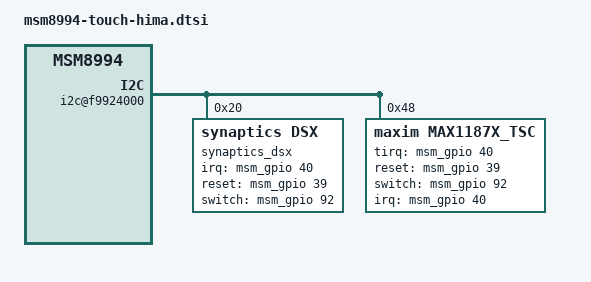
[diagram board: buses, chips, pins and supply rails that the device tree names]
&pmx_ts {
	qcom,pins = <&gp 40>;
	qcom,pin-func = <0>;
	qcom,num-grp-pins = <1>;
};

&ts_active {
	drive-strength = <2>;
	bias-pull-up;
};

&ts_suspend {
	drive-strength = <2>;
	bias-pull-up;
};

&soc {
	touch_fw_update {
		compatible = "htc,touch_fwu";
	};

	i2c@f9924000 {
		synaptics_dsx@20 {
			compatible = "synaptics,dsx";
			reg = <0x20>;
			interrupt-parent = <&msm_gpio>;
			interrupts = <40 0x2>;
			synaptics,irq-gpio = <&msm_gpio 40 0x00>;
			synaptics,irq-flags = <0x2008>;
			synaptics,reset-gpio = <&msm_gpio 39 0x00>;
			synaptics,reset-on-state = <0>;
			synaptics,reset-active-ms = <1>;
			synaptics,reset-delay-ms = <20>;
			synaptics,switch-gpio = <&msm_gpio 92 0x00>;
			synaptics,update-feature = <2>;
			synaptics,support-glove = <1>;
			synaptics,support-cover = <1>;
			synaptics,hall-block-time = <1000>;
			synaptics,display-coords = <0 1080 0 1920>;
			pinctrl-names = "pmx_ts_active", "pmx_ts_suspend";
			pinctrl-0 = <&ts_active>;
			pinctrl-1 = <&ts_suspend>;

			config_5 {
				pr_number     = <1826300>;
				uncover_setting = [FC C0 19 1E 80 08 52 48 01 D2];
				cover_setting = [FC C0 0D 0F 50 32 1A 0D 00 A0];
				glove_setting = [FA E6 19 1E 50 19 40 1A 00 D2];
				config = [
					02 12 00 00 04 2F 03 02
					05 37 04 7F 07 C3 41 F6
					40 00 00 20 00 0F 1B 01
					1E 05 E4 15 9E 05 28 37
					FE 3A FE 63 CA BE DA FC
					3C C0 C4 05 03 19 1E 80
					0F 0A 78 00 01 01 07 04
					04 32 28 08 C8 71 71 FF
					FF F1 F4 52 48 01 40 28
					2D FF 00 00 00 00 01 05
					0A 01 FF 00 D2 00 80 03
					1B 00 00 FF 64 00 FF FF
					A6 C8 00 7D 00 E6 80 00
					00 00 00 14 00 00 00 3A
					02 32 21 0C 0C 30 30 00
					31 1D 64 00 00 C8 00 01
					00 05 05 07 07 02 58 02
					01 03 01 14 00 14 00 00
					00 03 00 02 2C 81 14 00
					14 00 00 02 05 00 03 2C
					01 14 00 14 00 00 04 02
					00 01 28 01 14 00 14 00
					00 06 02 00 01 2A 81 14
					00 14 00 00 08 02 00 01
					2C 01 14 00 14 00 00 0A
					02 00 01 2C 83 26 00 26
					00 00 00 05 00 03 2C 83
					26 00 26 00 00 02 02 00
					01 28 03 26 00 26 00 00
					05 02 00 01 2A 02 21 00
					21 00 00 08 02 00 01 2D
					02 21 00 21 00 00 0C 05
					00 02 28 01 1C 00 1C 00
					00 0F 05 00 02 29 00 00
					00 00 00 00 00 00 00 00
					00 00 00 00 00 00 00 00
					00 00 1A 00 03 00 64 00
					14 0A 05 01 28 27 27 28
					01 01 34 00 03 00 00 00
					00 00 32 00 06 08 04 01
					07 02 01 02 00 1B 10 08
					03 11 05 73 0A C8 14 30
					46 80 05 14 B4 04 01 02
					00 04 0D 18 16 15 14 13
					12 0F 0E 0C 0B 0A 09 08
					04 07 FF FF FF FF FF 00
					01 02 03 04 05 06 07 08
					09 0A 0B 0C 0D 0E 0F 10
					11 12 13 14 15 16 17 18
					19 1A FF FF FF FF FF 00
					10 00 10 00 10 00 10 73
					7A 80 80 80 80 80 80 80
					80 80 80 80 80 80 80 80
					80 7A 73 80 80 80 80 80
					80 80 80 80 80 80 80 80
					80 80 80 80 80 80 80 80
					80 80 80 80 80 80 80 80
					80 80 80 00 10 00 10 00
					10 00 10 00 44 20 01 04
					0A 05
				];
			};

			config_4 {
				pr_number     = <1817745>;
				config = [
					20 15 01 19 00 2F 03 02
					05 37 04 7F 07 C3 41 F6
					40 00 00 00 00 0F 1B 01
					1E 05 E4 15 9E 05 28 37
					FE 3A FE 63 CA BE DA AA
					3C E6 C4 05 05 19 1E 80
					0F 0A 78 00 01 01 07 04
					04 1E 28 19 C8 71 71 FF
					FF F1 F4 52 48 00 40 28
					2D FF 00 00 00 00 01 05
					0A 01 FF 00 D2 00 80 03
					1B 00 00 FF 64 00 FF FF
					BF 96 00 7D 00 E6 80 00
					00 00 00 14 00 00 00 3A
					02 32 21 0C 0C 30 30 00
					31 01 64 00 00 C8 00 01
					00 05 05 07 07 02 64 00
					01 03 01 14 00 14 00 00
					00 03 00 02 2C 81 14 00
					14 00 00 02 05 00 03 2C
					01 14 00 14 00 00 04 02
					00 01 28 01 14 00 14 00
					00 06 02 00 01 2A 81 14
					00 14 00 00 08 02 00 01
					2C 01 14 00 14 00 00 0A
					02 00 01 2C 83 26 00 26
					00 00 00 05 00 03 2C 83
					26 00 26 00 00 02 02 00
					01 28 03 26 00 26 00 00
					05 02 00 01 2A 02 21 00
					21 00 00 08 02 00 01 2D
					02 21 00 21 00 00 0C 05
					00 02 28 01 1C 00 1C 00
					00 0F 05 00 02 29 00 00
					00 00 00 00 00 00 00 00
					00 00 00 00 00 00 00 00
					00 00 1A 00 03 00 A6 00
					14 0A 05 01 28 27 27 28
					01 01 34 00 03 00 00 00
					00 00 32 00 06 08 04 01
					07 02 01 02 00 1B 18 0C
					03 11 05 73 0A C8 14 20
					46 80 05 14 B4 04 01 02
					00 04 0D 18 16 15 14 13
					12 0F 0E 0C 0B 0A 09 08
					04 07 FF FF FF FF FF 00
					01 02 03 04 05 06 07 08
					09 0A 0B 0C 0D 0E 0F 10
					11 12 13 14 15 16 17 18
					19 1A FF FF FF FF FF 00
					10 00 10 00 10 00 10 73
					7A 80 80 80 80 80 80 80
					80 80 80 80 80 80 80 80
					80 7A 73 80 80 80 80 80
					80 80 80 80 80 80 80 80
					80 80 80 80 80 80 80 80
					80 80 80 80 80 80 80 80
					80 80 80 00 10 00 10 00
					10 00 10 00 44 20 01 02
					0A 02
				];
			};

			config_3 {
				pr_number     = <1812806>;
				config = [
					20 14 01 08 04 0F 03 02
					05 37 04 7F 07 C3 41 F6
					40 00 00 00 00 0F 1B 01
					1E 05 E4 15 9E 05 2D 37
					FE 3A FE 63 CA BE DA AA
					3C E6 C4 05 05 19 1E 80
					0F 0A 78 00 01 01 07 04
					04 0A C0 0A C8 71 71 FF
					FF F1 F4 40 19 00 40 28
					26 FF 00 00 00 00 01 21
					0A 01 FF 00 D2 00 80 03
					1B 00 00 FF 64 00 FF FF
					BF 96 00 7D 00 E6 80 00
					00 00 00 14 00 00 00 3A
					02 32 21 0C 0C 30 30 00
					31 01 64 00 00 C8 00 01
					00 05 05 07 07 02 64 00
					01 03 01 14 00 14 00 00
					00 03 00 02 2C 81 14 00
					14 00 00 02 05 00 03 2C
					01 14 00 14 00 00 04 02
					00 01 28 01 14 00 14 00
					00 06 02 00 01 2A 81 14
					00 14 00 00 08 02 00 01
					2C 01 14 00 14 00 00 0A
					02 00 01 2C 83 26 00 26
					00 00 00 05 00 03 2C 83
					26 00 26 00 00 02 02 00
					01 28 03 26 00 26 00 00
					05 02 00 01 2A 02 21 00
					21 00 00 08 02 00 01 2D
					02 21 00 21 00 00 0C 05
					00 02 28 01 1C 00 1C 00
					00 0F 05 00 02 29 00 00
					00 00 00 00 00 00 00 00
					00 00 00 00 00 00 00 00
					00 00 1A 00 03 00 A6 00
					14 0A 05 01 28 27 27 28
					01 01 34 00 03 00 00 00
					00 00 32 00 06 08 04 01
					07 02 01 02 00 1B 18 0C
					03 11 05 73 0A C8 14 20
					46 80 05 14 B4 04 01 02
					00 04 0D 18 16 15 14 13
					12 0F 0E 0C 0B 0A 09 08
					04 07 FF FF FF FF FF 00
					01 02 03 04 05 06 07 08
					09 0A 0B 0C 0D 0E 0F 10
					11 12 13 14 15 16 17 18
					19 1A FF FF FF FF FF 00
					10 00 10 00 10 00 10 73
					7A 80 80 80 80 80 80 80
					80 80 80 80 80 80 80 80
					80 7A 73 80 80 80 80 80
					80 80 80 80 80 80 80 80
					80 80 80 80 80 80 80 80
					80 80 80 80 80 80 80 80
					80 80 80 00 10 00 10 00
					10 00 10 00 55 50 01 02
					0A 02
				];
			};

			config_2 {
				pr_number     = <1776733>;
				config = [
					20 14 12 11 04 0F 03 02
					05 37 04 7F 07 C3 41 F6
					40 00 00 00 00 0F 1B 01
					1E 05 E4 15 9E 05 2D 37
					FE 3A FE 63 CA BE DA AA
					3C E6 C4 05 05 19 1E 80
					0F 0A 78 00 01 01 07 04
					04 0A C0 19 C8 71 71 FF
					FF F1 F4 40 19 00 40 28
					26 FF 00 00 00 00 01 21
					0A 01 FF 00 D2 00 80 03
					1B 00 00 FF 64 00 FF FF
					BF 96 00 7D 00 E6 80 80
					0A 00 00 00 00 14 00 00
					00 3A 02 32 21 0C 0C 30
					30 00 31 01 64 00 00 C8
					00 01 00 05 05 07 07 02
					64 00 01 03 01 14 00 14
					00 00 00 03 00 02 2C 81
					14 00 14 00 00 02 05 00
					03 2C 01 14 00 14 00 00
					04 02 00 01 28 01 14 00
					14 00 00 06 02 00 01 2A
					81 14 00 14 00 00 08 02
					00 01 2C 01 14 00 14 00
					00 0A 02 00 01 2C 83 26
					00 26 00 00 00 05 00 03
					2C 83 26 00 26 00 00 02
					02 00 01 28 03 26 00 26
					00 00 05 02 00 01 2A 02
					21 00 21 00 00 08 02 00
					01 2D 02 21 00 21 00 00
					0C 05 00 02 28 01 1C 00
					1C 00 00 0F 05 00 02 29
					00 00 00 00 00 00 00 00
					00 00 00 00 00 00 00 00
					00 00 00 00 1A 00 03 00
					A6 00 14 0A 05 01 28 27
					27 28 01 01 34 00 03 00
					00 00 00 00 32 00 06 08
					04 01 07 02 01 02 00 1B
					18 0C 03 11 05 73 0A C8
					14 20 46 80 05 14 B4 04
					01 02 00 04 00 00 00 FF
					FF FF FF FF FF FF FF 51
					51 51 51 CD 0D 04 83 10
					10 10 10 0D 18 16 15 14
					13 12 0F 0E 0C 0B 0A 09
					08 04 07 FF FF FF FF FF
					00 01 02 03 04 05 06 07
					08 09 0A 0B 0C 0D 0E 0F
					10 11 12 13 14 15 16 17
					18 19 1A FF FF FF FF FF
					00 10 00 10 00 10 00 10
					73 7A 80 80 80 80 80 80
					80 80 80 80 80 80 80 80
					80 80 7A 73 80 80 80 80
					80 80 80 80 80 80 80 80
					80 80 80 80 80 80 80 80
					80 80 80 80 80 80 80 80
					80 80 80 80 00 10 00 10
					00 10 00 10 00 37 37 01
					02 0A 02
				];
			};

			config_1 {
				pr_number     = <1774299>;
				config = [
					20 14 11 06 04 0F 03 02
					05 37 04 7F 07 C3 41 F6
					40 00 00 00 00 0F 1B 01
					1E 05 E4 15 9E 05 2D 37
					FE 3A FE 63 CA BE DA AA
					3C E6 C4 05 05 19 1E 80
					0F 0A 8C 00 01 01 07 04
					04 0A C0 19 C8 71 71 FF
					FF F1 F4 40 19 00 40 40
					32 FF 00 00 00 00 00 21
					0A 01 FF 00 D2 00 80 03
					1B 00 00 FF 64 00 FF FF
					BF 96 D0 07 00 C0 80 80
					0A 00 00 00 00 14 00 00
					00 3A 02 32 21 0C 0C 30
					30 00 31 01 64 00 00 C8
					00 01 00 05 05 07 07 02
					F4 01 01 03 01 14 00 14
					00 00 00 03 00 02 2C 01
					14 00 14 00 02 00 05 00
					03 2C 01 14 00 14 00 04
					00 02 00 01 28 01 14 00
					14 00 06 00 02 00 01 2A
					81 14 00 14 00 08 00 02
					00 01 2C 01 14 00 14 00
					0A 00 02 00 01 2C 03 26
					00 26 00 00 00 05 00 03
					2C 03 26 00 26 00 00 02
					02 00 01 28 03 26 00 26
					00 00 05 02 00 01 2A 02
					21 00 21 00 00 08 02 00
					01 2D 02 21 00 21 00 00
					0C 05 00 02 28 01 1C 00
					1C 00 00 0F 05 00 02 29
					00 00 00 00 00 00 00 00
					00 00 00 00 00 00 00 00
					00 00 00 00 1A 00 03 00
					A6 00 14 0A 05 01 28 27
					27 28 01 01 34 00 03 00
					00 00 00 00 32 00 06 08
					04 01 07 02 01 02 00 1B
					10 0C 03 11 0A 73 0A C8
					14 20 46 80 03 14 00 04
					01 02 00 04 00 00 00 FF
					FF FF FF FF FF FF FF 51
					51 51 51 CD 0D 04 83 10
					10 10 10 0D 18 16 15 14
					13 12 0F 0E 0C 0B 0A 09
					08 04 07 FF FF FF FF FF
					00 01 02 03 04 05 06 07
					08 09 0A 0B 0C 0D 0E 0F
					10 11 12 13 14 15 16 17
					18 19 1A FF FF FF FF FF
					00 10 00 10 00 10 00 10
					80 80 80 80 80 80 80 80
					80 80 80 80 80 80 80 80
					80 80 80 80 80 80 80 80
					80 80 80 80 80 80 80 80
					80 80 80 80 80 80 80 80
					80 80 80 80 80 80 80 80
					80 80 80 80 00 10 00 10
					00 10 00 10 00 37 37 00
					00 02 0A 00
				];
			};

			config_0 {
				pr_number     = <1757676>;
				config = [
					20 14 10 17 04 0E 03 02
					05 37 04 7F 07 C3 41 F6
					40 00 00 00 00 0F 1B 01
					1E 05 E4 15 9E 05 2D 37
					FE 3A FE 63 CA BE DA 86
					80 C4 C4 05 03 20 32 80
					0F 0A 20 00 01 01 07 04
					04 0A C0 19 64 26 26 80
					80 00 00 6E 19 01 40 40
					32 FF 00 00 00 00 00 00
					25 0A 01 FF 00 D3 00 80
					04 1B 00 00 FF 63 07 FF
					FF BF 96 B8 0B 00 C0 80
					80 0A 00 00 00 00 14 00
					00 00 3A 02 32 21 0C 0C
					30 30 00 31 1D 66 00 00
					28 00 63 00 04 04 00 00
					00 B1 08 01 03 00 1C 00
					14 00 00 00 02 00 01 2B
					00 1C 00 14 00 00 02 02
					00 01 28 80 1C 00 14 00
					00 05 02 00 01 2A 80 1A
					00 14 00 00 08 02 00 01
					2D 80 1A 00 14 00 00 0A
					05 00 02 28 80 1A 00 14
					00 00 0A 05 00 02 29 83
					26 00 26 00 00 00 05 00
					03 2C 83 26 00 26 00 00
					02 02 00 01 28 83 26 00
					26 00 00 05 02 00 01 2A
					83 26 00 26 00 00 08 02
					00 01 2D 83 26 00 26 00
					00 0A 05 00 02 28 83 26
					00 26 00 00 0A 05 00 02
					29 03 04 07 03 06 06 06
					06 06 06 06 03 03 03 03
					00 00 00 00 00 18 00 03
					00 A6 00 14 64 05 01 28
					27 27 28 02 35 01 01 34
					00 03 00 02 00 00 00 32
					00 00 08 04 01 07 02 01
					02 00 1B 1C 0C 03 11 0A
					32 0A 32 14 20 46 80 03
					14 4B 04 01 02 00 04 00
					00 00 FF FF FF FF FF FF
					FF FF 51 51 51 51 CD 0D
					04 83 10 10 10 10 0D 18
					16 15 14 13 12 0F 0E 0C
					0B 0A 09 08 04 07 FF FF
					FF FF FF 00 01 02 03 04
					05 06 07 08 09 0A 0B 0C
					0D 0E 0F 10 11 12 13 14
					15 16 17 18 19 1A FF FF
					FF FF FF 00 10 00 10 00
					10 00 10 80 80 80 80 80
					80 80 80 80 80 80 80 80
					80 80 80 80 80 80 80 80
					80 80 80 80 80 80 80 80
					80 80 80 80 80 80 80 80
					80 80 80 80 80 80 80 80
					80 80 80 80 80 80 80 00
					10 00 10 00 10 00 10 00
					FF
				];
			};
		};

		maxim@48 {
			compatible = "maxim,max1187x_tsc";
			reg = <0x48>;
			interrupt-parent = <&msm_gpio>;
			interrupts = <40 0>;
			gpio_tirq = <&msm_gpio 40 0x00>;
			gpio_reset = <&msm_gpio 39 0x00>;
			gpio_switch = <&msm_gpio 92 0x00>;
			num_fw_mappings = <1>;
			chip_id = <0x78>;
			filename = "max11876a.bin";
			filesize = <0xC000>;
			file_codesize = <0xC000>;
			defaults_allow = <1>;
			default_config_id = <0x46D0>;
			default_chip_id = <0x78>;
			i2c_words = <123>;
			coordinate_settings = <0x4>;
			panel_min_x = <0>;
			panel_max_x = <1620>;
			panel_min_y = <0>;
			panel_max_y = <2880>;
			lcd_x = <1080>;
			lcd_y = <1920>;
			num_rows = <28>;
			num_cols = <16>;
			input_protocol = <1>;
			button_code0 = <0>;
			button_code1 = <0>;
			button_code2 = <0>;
			button_code3 = <0>;
			update_feature = <2>;
			tw_mask = <0xF>;
			report_mode = <2>;
			hall_block_touch_time = <1000>;
			pinctrl-names = "pmx_ts_active", "pmx_ts_suspend";
			pinctrl-0 = <&ts_active>;
			pinctrl-1 = <&ts_suspend>;

			config3 {
				config_id = <0x46D0>;
				chip_id = <0x78>;
				major_ver = <1>;
				minor_ver = <31>;
				protocol_ver = <8>;
				vendor_pin = <0xC>;
				support_glove = <1>;
				support_cover = <1>;
				filter_range = <0 30 75 75>;
				config_touch = [
					46D0 101C 007D 001E 0A02 0809 0704 0605
					FF03 FF02 01FF 00FF FF0D 0B0A 0C0E 0FFF
					11FF 1210 FFFF 1513 FF14 1716 1918 FFFF
					1B1A 0100 0302 0504 0706 0908 0B0A 0D0C
					0F0E FFFF FFFF FFFF FFFF FFFF FFFF FFFF
					FFFF 0B3F 8653 0513 0001 0502 079E 03E8
					0A8C 05DC 00A0 0D00 0A05 FFFF FFFF FFFF
					FFFF 03E8 FFFF FFFF FFFF FFFF FFFF FFFF
					3487
				];
				config_cal = [
					FFF5 FFEA FFDF 001C 001C 001C 001C 001C
					001C 001C 001C 001C 001C 001C 001C 001C
					001C 001C 001C 001C 001C 001C 001C 001C
					001C 001C 001C 0003 0003 0003 0003 0003
					0003 0003 0003 0003 0003 0003 0003 0003
					0003 0003 0003 0000 0000 0000 0000 0000
					0000 0000 0000 FFFF FF1E 00FF 010E 010E
					0104 00E1 0113 0113 00F5 00F5 000A 0001
					0001 0002 0002 0003 0001 0001 0002 0002
					0003 0AD7
				];
				config_private = [
					01E0 00FA 002D 038B FB08 0028 001E 0190
					02EE 00AA 0064 0018 04E2 0096 0000 B232
					0000 3200 FEFE FFFF 00FF FF15 4E21 0503
					7896 52EE FFFF FFFF FFFF FFFF FFFF FFFF
					FFFF 0EE0
				];
				config_lin_x = [
					002D 361E 664E 8D7D AD9D CDBD EDDD 934D
				];
				config_lin_y = [
					0030 3820 6850 9080 B0A0 D0C0 F0E0 A360
				];
			};

			config2 {
				config_id = <0x4301>;
				chip_id = <0x78>;
				major_ver = <1>;
				minor_ver = <31>;
				protocol_ver = <8>;
				vendor_pin = <0xD>;
				support_glove = <1>;
				support_cover = <1>;
				filter_range = <0 30 75 75>;
				config_touch = [
					46D0 101C 007D 001E 0A02 0809 0704 0605
					FF03 FF02 01FF 00FF FF0D 0B0A 0C0E 0FFF
					11FF 1210 FFFF 1513 FF14 1716 1918 FFFF
					1B1A 0100 0302 0504 0706 0908 0B0A 0D0C
					0F0E FFFF FFFF FFFF FFFF FFFF FFFF FFFF
					FFFF 0B3F 8653 0513 0001 0502 079E 03E8
					0A8C 05DC 00A0 0D00 0A05 FFFF FFFF FFFF
					FFFF 03E8 FFFF FFFF FFFF FFFF FFFF FFFF
					3487
				];
				config_cal = [
					FFF5 FFEA FFDF 001C 001C 001C 001C 001C
					001C 001C 001C 001C 001C 001C 001C 001C
					001C 001C 001C 001C 001C 001C 001C 001C
					001C 001C 001C 0003 0003 0003 0003 0003
					0003 0003 0003 0003 0003 0003 0003 0003
					0003 0003 0003 0000 0000 0000 0000 0000
					0000 0000 0000 FFFF FF1E 00FF 010E 010E
					0104 00E1 0113 0113 00F5 00F5 000A 0001
					0001 0002 0002 0003 0001 0001 0002 0002
					0003 0AD7
				];
				config_private = [
					01E0 00FA 002D 038B FB08 0028 001E 0190
					02EE 00AA 0064 0018 04E2 0096 0000 B232
					0000 3200 FEFE FFFF 00FF FF15 4E21 0503
					7896 52EE FFFF FFFF FFFF FFFF FFFF FFFF
					FFFF 0EE0
				];
				config_lin_x = [
					002D 361E 664E 8D7D AD9D CDBD EDDD 934D
				];
				config_lin_y = [
					0030 3820 6850 9080 B0A0 D0C0 F0E0 A360
				];
			};

			config1 {
				config_id = <0x0067>;
				chip_id = <0x78>;
				major_ver = <1>;
				minor_ver = <30>;
				protocol_ver = <8>;
				vendor_pin = <0xC>;
				config_touch = [
					0067 101C 0078 001E 0A01 0809 0704 0605
					FF03 FF02 01FF 00FF FF0D 0B0A 0C0E 0FFF
					11FF 1210 FFFF 1513 FF14 1716 1918 FFFF
					1B1A 0100 0302 0504 0706 0908 0B0A 0D0C
					0F0E FFFF FFFF FFFF FFFF FFFF FFFF FFFF
					FFFF 0B3F 8653 0111 0001 3202 0708 0898
					0578 04B0 0096 1900 0A0A FFFF FFFF FFFF
					FFFF 03E8 FFFF FFFF FFFF FFFF FFFF FFFF
					20EB
				];
				config_cal = [
					FFF5 FFEA FFDF 001C 001C 001C 001C 001C
					001C 001C 001C 001C 001C 001C 001C 001C
					001C 001C 001C 001C 001C 001C 001C 001C
					001C 001C 001C 0003 0003 0003 0003 0003
					0003 0003 0003 0003 0003 0003 0003 0003
					0003 0003 0003 0000 0000 0000 0000 0000
					0000 0000 0000 FFFF FF1E 00FF 00FF 00FF
					00FF 00FF 00FF 00FF 00FF 00FF 000A 0001
					0001 0002 0002 0003 0001 0001 0002 0002
					0003 0ABE
				];
				config_private = [
					0118 0069 0064 0038 F0FF 1428 001E 0190
					03B6 00AA 0064 0018 04E2 003C 1400 B232
					FFFF FF00 FEFE FFFF 00FF FF15 4E21 0DC3
					7864 524C FFFF FFFF FFFF FFFF FFFF FFFF
					FFFF FDBB
				];
				config_lin_x = [
					002B 3016 644C 8876 AA99 CBBB F0E0 8437
				];
				config_lin_y = [
					0030 2E17 664B 8F7D AE9F CABC EADA 8844
				];
			};

			config0 {
				config_id = <0x5700>;
				chip_id = <0x78>;
				major_ver = <1>;
				minor_ver = <30>;
				protocol_ver = <8>;
				vendor_pin = <0xF>;
				config_touch = [
					5700 1420 0078 001E 0A02 090C 0B07 0608
					FF03 0502 010A 0004 FF0E 0D10 FF11 12FF
					0FFF 13FF 14FF 1915 FF16 171B 181C 1D1A
					1F1E FFFF 0100 0302 0504 0706 0908 0B0A
					0D0C 0F0E 1110 1312 FFFF 1300 1301 FFFF
					FFFF 0B3F 8653 FF13 0001 1402 0834 0AF0
					06A4 04B0 01F4 1A00 1408 0046 0028 FFFF
					FFFF 0BB8 FFFF FFFF FFFF FFFF FFFF FFFF
					F93C
				];
				config_cal = [
					FFF5 FFEA FFDF 001C 001C 001C 001C 001C
					001C 001C 001C 001C 001C 001C 001C 001C
					001C 001C 001C 001C 001C 001C 001C 001C
					001C 001C 001C 0002 0002 0003 0003 0003
					0003 0003 0003 0003 0003 0003 0003 0003
					0003 0003 0003 0003 0003 0003 0003 0003
					0003 0003 0003 FFFF FF1E 00FF 012C 012C
					0118 00FF 0140 0140 0140 0140 000A 0001
					0001 0002 0002 0003 0001 0001 0002 0002
					0003 0C4B
				];
				config_private = [
					0118 0069 0032 0248 E206 1428 001E 0190
					03B6 00AA 0064 0018 04E2 0032 1400 B232
					FEFD 32FF FEFE FFFF 00FF FF55 4E21 0DC3
					7864 524C FFFF FFFF FFFF FFFF FFFF FFFF
					FFFF 23D3
				];
				config_lin_x = [
					002B 3016 644C 8876 AA99 CBBB F0E0 8437
				];
				config_lin_y = [
					0030 2E17 664B 8F7D AE9F CABC EADA 8844
				];
			};
		};
	};
};

